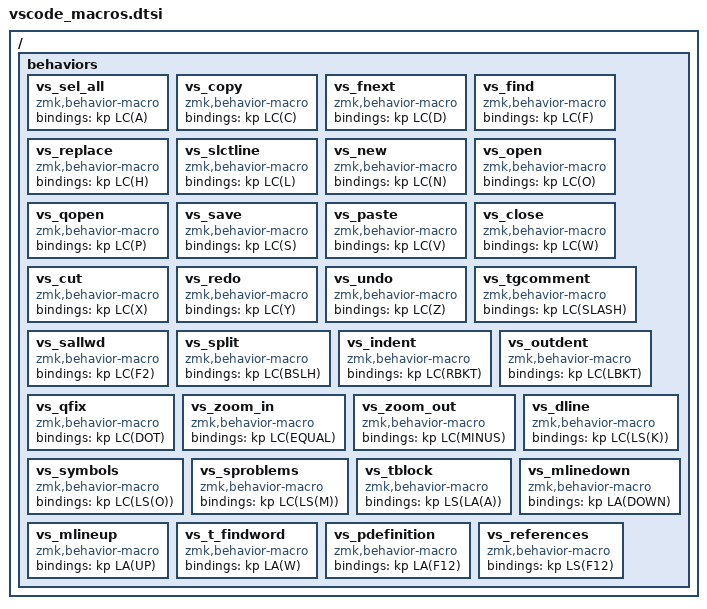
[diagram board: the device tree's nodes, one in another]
/ {
  behaviors {
    /* VS Code (Ctrl+) */
    vs_sel_all:   vs_sel_all   { compatible = "zmk,behavior-macro"; #binding-cells = <0>; bindings = <&kp LC(A)>; };
    vs_copy:      vs_copy      { compatible = "zmk,behavior-macro"; #binding-cells = <0>; bindings = <&kp LC(C)>; };
    vs_fnext:     vs_fnext     { compatible = "zmk,behavior-macro"; #binding-cells = <0>; bindings = <&kp LC(D)>; };
    vs_find:      vs_find      { compatible = "zmk,behavior-macro"; #binding-cells = <0>; bindings = <&kp LC(F)>; };
    vs_replace:   vs_replace   { compatible = "zmk,behavior-macro"; #binding-cells = <0>; bindings = <&kp LC(H)>; };
    vs_slctline:  vs_slctline  { compatible = "zmk,behavior-macro"; #binding-cells = <0>; bindings = <&kp LC(L)>; };
    vs_new:       vs_new       { compatible = "zmk,behavior-macro"; #binding-cells = <0>; bindings = <&kp LC(N)>; };
    vs_open:      vs_open      { compatible = "zmk,behavior-macro"; #binding-cells = <0>; bindings = <&kp LC(O)>; };
    vs_qopen:     vs_qopen     { compatible = "zmk,behavior-macro"; #binding-cells = <0>; bindings = <&kp LC(P)>; };
    vs_save:      vs_save      { compatible = "zmk,behavior-macro"; #binding-cells = <0>; bindings = <&kp LC(S)>; };
    vs_paste:     vs_paste     { compatible = "zmk,behavior-macro"; #binding-cells = <0>; bindings = <&kp LC(V)>; };
    vs_close:     vs_close     { compatible = "zmk,behavior-macro"; #binding-cells = <0>; bindings = <&kp LC(W)>; };
    vs_cut:       vs_cut       { compatible = "zmk,behavior-macro"; #binding-cells = <0>; bindings = <&kp LC(X)>; };
    vs_redo:      vs_redo      { compatible = "zmk,behavior-macro"; #binding-cells = <0>; bindings = <&kp LC(Y)>; };
    vs_undo:      vs_undo      { compatible = "zmk,behavior-macro"; #binding-cells = <0>; bindings = <&kp LC(Z)>; };

    /* Otros */
    vs_tgcomment: vs_tgcomment { compatible = "zmk,behavior-macro"; #binding-cells=<0>; bindings = <&kp LC(SLASH)>; };
    vs_sallwd:    vs_sallwd    { compatible = "zmk,behavior-macro"; #binding-cells=<0>; bindings = <&kp LC(F2)>; };
    vs_split:     vs_split     { compatible = "zmk,behavior-macro"; #binding-cells=<0>; bindings = <&kp LC(BSLH)>; };
    vs_indent:    vs_indent    { compatible = "zmk,behavior-macro"; #binding-cells=<0>; bindings = <&kp LC(RBKT)>; };
    vs_outdent:   vs_outdent   { compatible = "zmk,behavior-macro"; #binding-cells=<0>; bindings = <&kp LC(LBKT)>; };
    vs_qfix:      vs_qfix      { compatible = "zmk,behavior-macro"; #binding-cells=<0>; bindings = <&kp LC(DOT)>; };
    vs_zoom_in:   vs_zoom_in   { compatible = "zmk,behavior-macro"; #binding-cells=<0>; bindings = <&kp LC(EQUAL)>; };
    vs_zoom_out:  vs_zoom_out  { compatible = "zmk,behavior-macro"; #binding-cells=<0>; bindings = <&kp LC(MINUS)>; };

    /* Con múltiples modificadores */
    vs_dline:     vs_dline     { compatible = "zmk,behavior-macro"; #binding-cells=<0>; bindings = <&kp LC(LS(K))>; };
    vs_symbols:   vs_symbols   { compatible = "zmk,behavior-macro"; #binding-cells=<0>; bindings = <&kp LC(LS(O))>; };
    vs_sproblems: vs_sproblems { compatible = "zmk,behavior-macro"; #binding-cells=<0>; bindings = <&kp LC(LS(M))>; };
    vs_tblock:    vs_tblock    { compatible = "zmk,behavior-macro"; #binding-cells=<0>; bindings = <&kp LS(LA(A))>; };

    /* Navegación */
    vs_mlinedown:  vs_mlinedown  { compatible = "zmk,behavior-macro"; #binding-cells=<0>; bindings = <&kp LA(DOWN)>; };
    vs_mlineup:    vs_mlineup    { compatible = "zmk,behavior-macro"; #binding-cells=<0>; bindings = <&kp LA(UP)>; };
    vs_t_findword: vs_t_findword { compatible = "zmk,behavior-macro"; #binding-cells=<0>; bindings = <&kp LA(W)>; };
    vs_pdefinition:vs_pdefinition{ compatible = "zmk,behavior-macro"; #binding-cells=<0>; bindings = <&kp LA(F12)>; };
    vs_references: vs_references { compatible = "zmk,behavior-macro"; #binding-cells=<0>; bindings = <&kp LS(F12)>; };
  };
};
